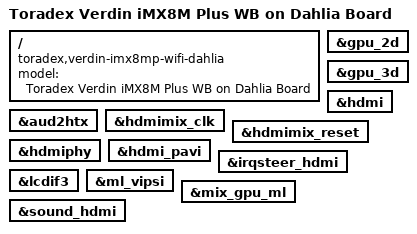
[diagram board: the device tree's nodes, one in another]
// SPDX-License-Identifier: GPL-2.0+ OR MIT
/*
 * Copyright 2020 Toradex
 */

/dts-v1/;

#include "imx8mp-verdin.dtsi"
#include "imx8mp-verdin-wifi.dtsi"
#include "imx8mp-verdin-dahlia.dtsi"

/ {
	model = "Toradex Verdin iMX8M Plus WB on Dahlia Board";
	compatible = "toradex,verdin-imx8mp-wifi-dahlia",
		     "toradex,verdin-imx8mp-wifi",
		     "toradex,verdin-imx8mp",
		     "fsl,imx8mp";
};

&aud2htx {
	status = "okay";
};

&gpu_2d {
	status = "okay";
};

&gpu_3d {
	status = "okay";
};

&hdmi {
	status = "okay";
};

&hdmimix_clk {
	status = "okay";
};

&hdmimix_reset {
	status = "okay";
};

&hdmiphy {
	status = "okay";
};

&hdmi_pavi {
	status = "okay";
};

&irqsteer_hdmi {
	status = "okay";
};

/* LCDIF to on-SoC Samsung HDMI PHY */
&lcdif3 {
	status = "okay";
};

&ml_vipsi {
	status = "okay";
};

&mix_gpu_ml {
	status = "okay";
};

&sound_hdmi {
	status = "okay";
};
